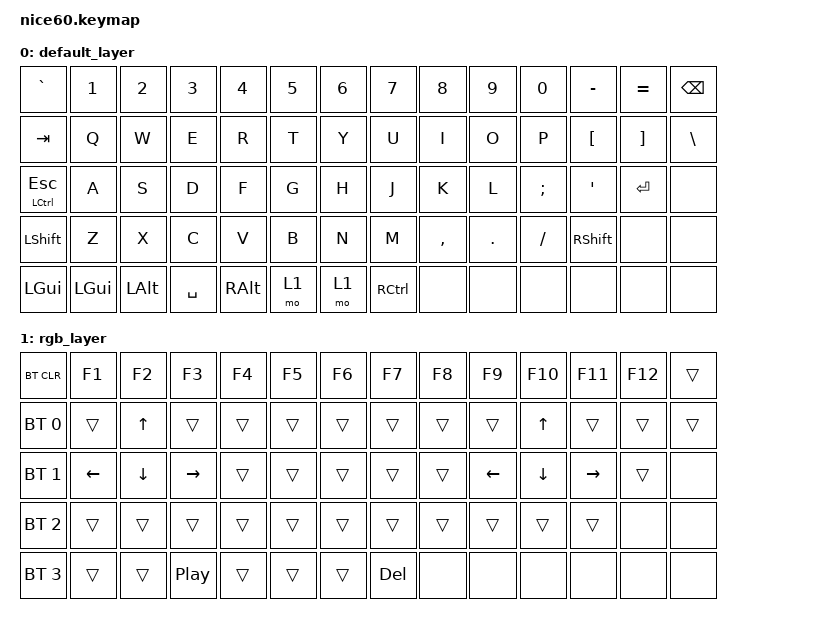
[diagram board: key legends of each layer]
/*
 * Copyright (c) 2021 Nick Winans
 *
 * SPDX-License-Identifier: MIT
 */

#include <behaviors.dtsi>
#include <dt-bindings/zmk/keys.h>
#include <dt-bindings/zmk/rgb.h>
#include <dt-bindings/zmk/bt.h>
#include <dt-bindings/zmk/outputs.h>
#include <dt-bindings/zmk/reset.h>
#include <dt-bindings/zmk/ext_power.h>

/ {
	keymap {
		compatible = "zmk,keymap";
		
		default_layer {
// ------------------------------------------------------------------------------------------
// | ESC |  1  |  2  |  3  |  4  |  5  |  6  |  7  |  8  |  9  |  0  |  -  |  =  |   BKSP   |
// | TAB  |  Q  |  W  |  E  |  R  |  T  |  Y  |  U  |  I  |  O  |  P  |  [  |  ]  |   "|"   |
// | CAPS  |  A  |  S  |  D  |  F  |  G  |  H  |  J  |  K  |  L  |  ;  |  '  |     ENTER    |
// |  SHIFT  |  Z  |  X  |  C  |  V  |  B  |  N  |  M  |  ,  |  .  |  /  |      SHIFT       |
// |  CTL  |  WIN  |  ALT  |            SPACE              |  ALT  |  WIN  |  MO(1) |  CTL  |
// ------------------------------------------------------------------------------------------
			bindings = <
    &kp GRAVE      &kp N1    &kp N2    &kp N3            &kp N4     &kp N5  &kp N6  &kp N7     &kp N8     &kp N9    &kp N0    &kp MINUS  &kp EQUAL  &kp BSPC
    &kp TAB        &kp Q     &kp W     &kp E             &kp R      &kp T   &kp Y   &kp U      &kp I      &kp O     &kp P     &kp LBKT   &kp RBKT   &kp BSLH
    &mt LCTRL ESC  &kp A     &kp S     &kp D             &kp F      &kp G   &kp H   &kp J      &kp K      &kp L     &kp SEMI  &kp SQT    &kp RET    &
    &kp LSHFT      &kp Z     &kp X     &kp C             &kp V      &kp B   &kp N   &kp M      &kp COMMA  &kp DOT   &kp FSLH  &kp RSHFT  &          &
    &kp LGUI       &kp LGUI  &kp LALT  &kp SPACE         &kp RALT   &mo 1   &mo 1   &kp RCTRL  &          &         &         &          &          &
			>;
                };

                rgb_layer {
			bindings = <
    &bt BT_CLR     &kp F1    &kp F2    &kp F3            &kp F4     &kp F5  &kp F6  &kp F7     &kp F8     &kp F9    &kp F10   &kp F11    &kp F12    &trans
    &bt BT_SEL 0   &trans    &kp UP    &trans            &trans     &trans  &trans  &trans     &trans     &trans    &kp UP    &trans     &trans     &trans 
    &bt BT_SEL 1   &kp LEFT  &kp DOWN  &kp RIGHT         &trans     &trans  &trans  &trans     &trans     &kp LEFT  &kp DOWN  &kp RIGHT  &trans     &
    &bt BT_SEL 2   &trans    &trans    &trans            &trans     &trans  &trans  &trans     &trans     &trans    &trans    &trans     &          &
    &bt BT_SEL 3   &trans    &trans    &kp C_PLAY_PAUSE  &trans     &trans  &trans  &kp DEL    &          &         &         &          &          &
			>;
		};
	};
};
